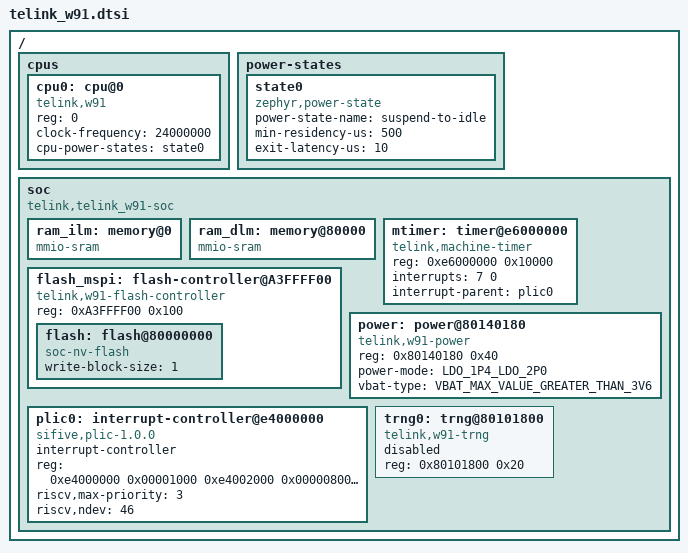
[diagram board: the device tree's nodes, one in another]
/*
 * Copyright (c) 2023 Telink Semiconductor
 *
 * SPDX-License-Identifier: Apache-2.0
 */

/dts-v1/;

/ {
	#address-cells = <1>;
	#size-cells = <1>;

	cpus {
		#address-cells = <1>;
		#size-cells = <0>;
		cpu0: cpu@0 {
			reg = <0>;
			clock-frequency = <24000000>;
			compatible ="telink,w91", "riscv";
			cpu-power-states = <&state0>;
		};
	};

	power-states {
		state0: state0 {
			compatible = "zephyr,power-state";
			power-state-name = "suspend-to-idle";
			min-residency-us = <500>;
			exit-latency-us = <10>;
		};
	};

	soc {
		#address-cells = <1>;
		#size-cells = <1>;
		compatible = "telink,telink_w91-soc";
		ranges;

		ram_ilm: memory@0 {
			compatible = "mmio-sram";
		};

		ram_dlm: memory@80000 {
			compatible = "mmio-sram";
		};

		mtimer: timer@e6000000 {
			compatible = "telink,machine-timer";
			reg = <0xe6000000 0x10000>;
			interrupts = <7 0>;
			interrupt-parent = <&plic0>;
		};

		flash_mspi: flash-controller@A3FFFF00 {
			compatible = "telink,w91-flash-controller";
			reg = <0xA3FFFF00 0x100>;

			#address-cells = <1>;
			#size-cells = <1>;

			flash: flash@80000000 {
				compatible = "soc-nv-flash";
				write-block-size = <1>;
			};
		};

		power: power@80140180 {
			compatible = "telink,w91-power";
			reg = <0x80140180 0x40>;
			power-mode = "LDO_1P4_LDO_2P0";
			vbat-type = "VBAT_MAX_VALUE_GREATER_THAN_3V6";
			status = "okay";
		};

		plic0: interrupt-controller@e4000000 {
			compatible = "sifive,plic-1.0.0";
			#address-cells = <0>;
			#interrupt-cells = <2>;
			interrupt-controller;
			reg = < 0xe4000000 0x00001000
					0xe4002000 0x00000800
					0xe4200000 0x00010000 >;
			reg-names = "prio", "irq_en", "reg";
			riscv,max-priority = <3>;
			riscv,ndev = <46>;
		};

		trng0: trng@80101800 {
			compatible = "telink,w91-trng";
			reg = <0x80101800 0x20>;
			status = "disabled";
		};
	};
};
